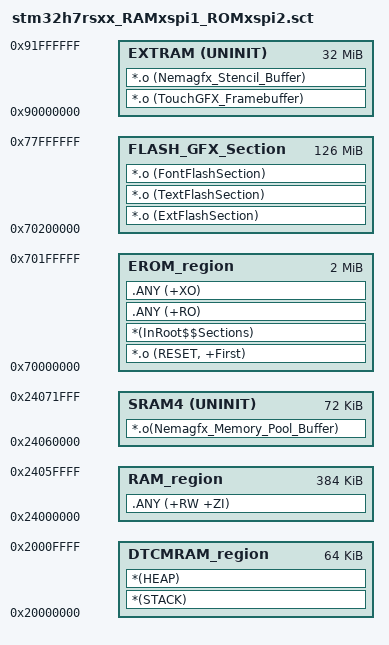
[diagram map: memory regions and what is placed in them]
; *************************************************************
; ***  Scatter-Loading Description File for STM32H7S78-DK   ***
; *************************************************************

EXTERNAL_FLASH 0x70000000 0x04000000 {    ; start addr, size
  EROM_region 0x70000000 0x200000  {
   *.o (RESET, +First)
   *(InRoot$$Sections)
   .ANY (+RO)
   .ANY (+XO)
  }

  RAM_region 0x24000000 0x60000  
  {
    .ANY (+RW +ZI)
  }

  SRAM4 0x24060000 UNINIT 0x12000
  {
    *.o(Nemagfx_Memory_Pool_Buffer)
  }
  
  DTCMRAM_region 0x20000000 0x00010000  
  {
   *(STACK)
   *(HEAP)
  }

  EXTRAM 0x90000000 UNINIT 0x02000000
  {
     *.o (TouchGFX_Framebuffer)
     *.o (Nemagfx_Stencil_Buffer)
  }
}

FLASH_GFX 0x70200000 0x07e00000 {
  FLASH_GFX_Section 0x70200000 0x07e00000 {
   *.o (ExtFlashSection)
   *.o (TextFlashSection)
   *.o (FontFlashSection)
  }
}

